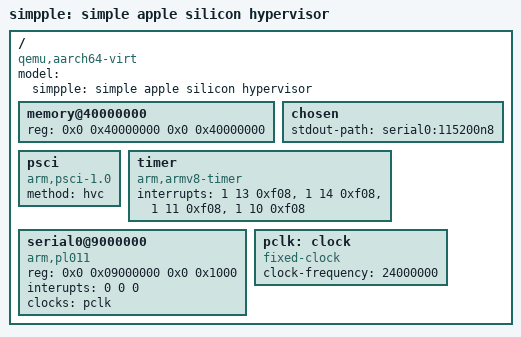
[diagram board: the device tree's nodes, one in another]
/dts-v1/;

/ {
    model = "simpple: simple apple silicon hypervisor";
    compatible = "qemu,aarch64-virt";
    
    #address-cells = <2>;
    #size-cells = <2>;
    
    memory@40000000 {
        device_type = "memory";
        reg = <0x0 0x40000000 0x0 0x40000000>; // 1GB
    };
    
    chosen {
        stdout-path = "serial0:115200n8";
    };

    psci {
      compatible = "arm,psci-1.0", "arm,psci-0.2";
      method = "hvc";
    };

    timer {
      compatible = "arm,armv8-timer";
      interrupts = <1 13 0xf08>,
                   <1 14 0xf08>,
                   <1 11 0xf08>,
                   <1 10 0xf08>;
    };
    
    serial0@9000000 {
        compatible = "arm,pl011", "arm,primecell";
        reg = <0x0 0x09000000 0x0 0x1000>;
        interupts = <0 0 0>;
        clocks = <&pclk>;
        clock-names = "apb_pclk";
    };
    
    pclk: clock {
        compatible = "fixed-clock";
        #clock-cells = <0>;
        clock-frequency = <24000000>;
    };
};
